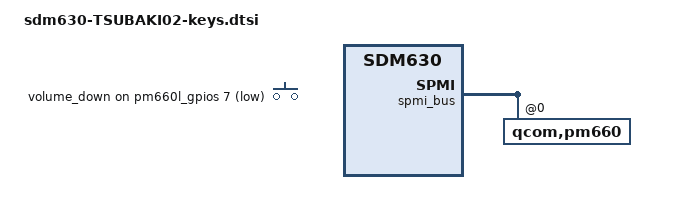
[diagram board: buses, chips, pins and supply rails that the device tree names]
/*
 * This software is contributed or developed by KYOCERA Corporation.
 * (C) 2018 KYOCERA Corporation
 *
 * This program is free software; you can redistribute it and/or modify
 * it under the terms of the GNU General Public License version 2 and
 * only version 2 as published by the Free Software Foundation.
 *
 * This program is distributed in the hope that it will be useful,
 * but WITHOUT ANY WARRANTY; without even the implied warranty of
 * MERCHANTABILITY or FITNESS FOR A PARTICULAR PURPOSE.  See the
 * GNU General Public License for more details.
 */

&spmi_bus {
	qcom,pm660@0 {
		qcom,power-on@800 {
			qcom,pon_2 {
				qcom,pon-type = <1>;
				qcom,pull-up = <1>;
				linux,code = <115>;
			};
		};
	};
};

&soc {

	/delete-node/ gpio_keys;

	gpio_keys {
		status = "okay";
		compatible = "gpio-keys";
		input-name = "gpio-keys";

		vol_down {
			label = "volume_down";
			gpios = <&pm660l_gpios 7 0x1>;
			linux,input-type = <1>;
			linux,code = <114>;
			gpio-key,wakeup;
			debounce-interval = <20>;
			on_chattering_num  = <1>;
			off_chattering_num = <0>;
		};
	};

	/delete-node/ tlmm_gpio_key;

};
